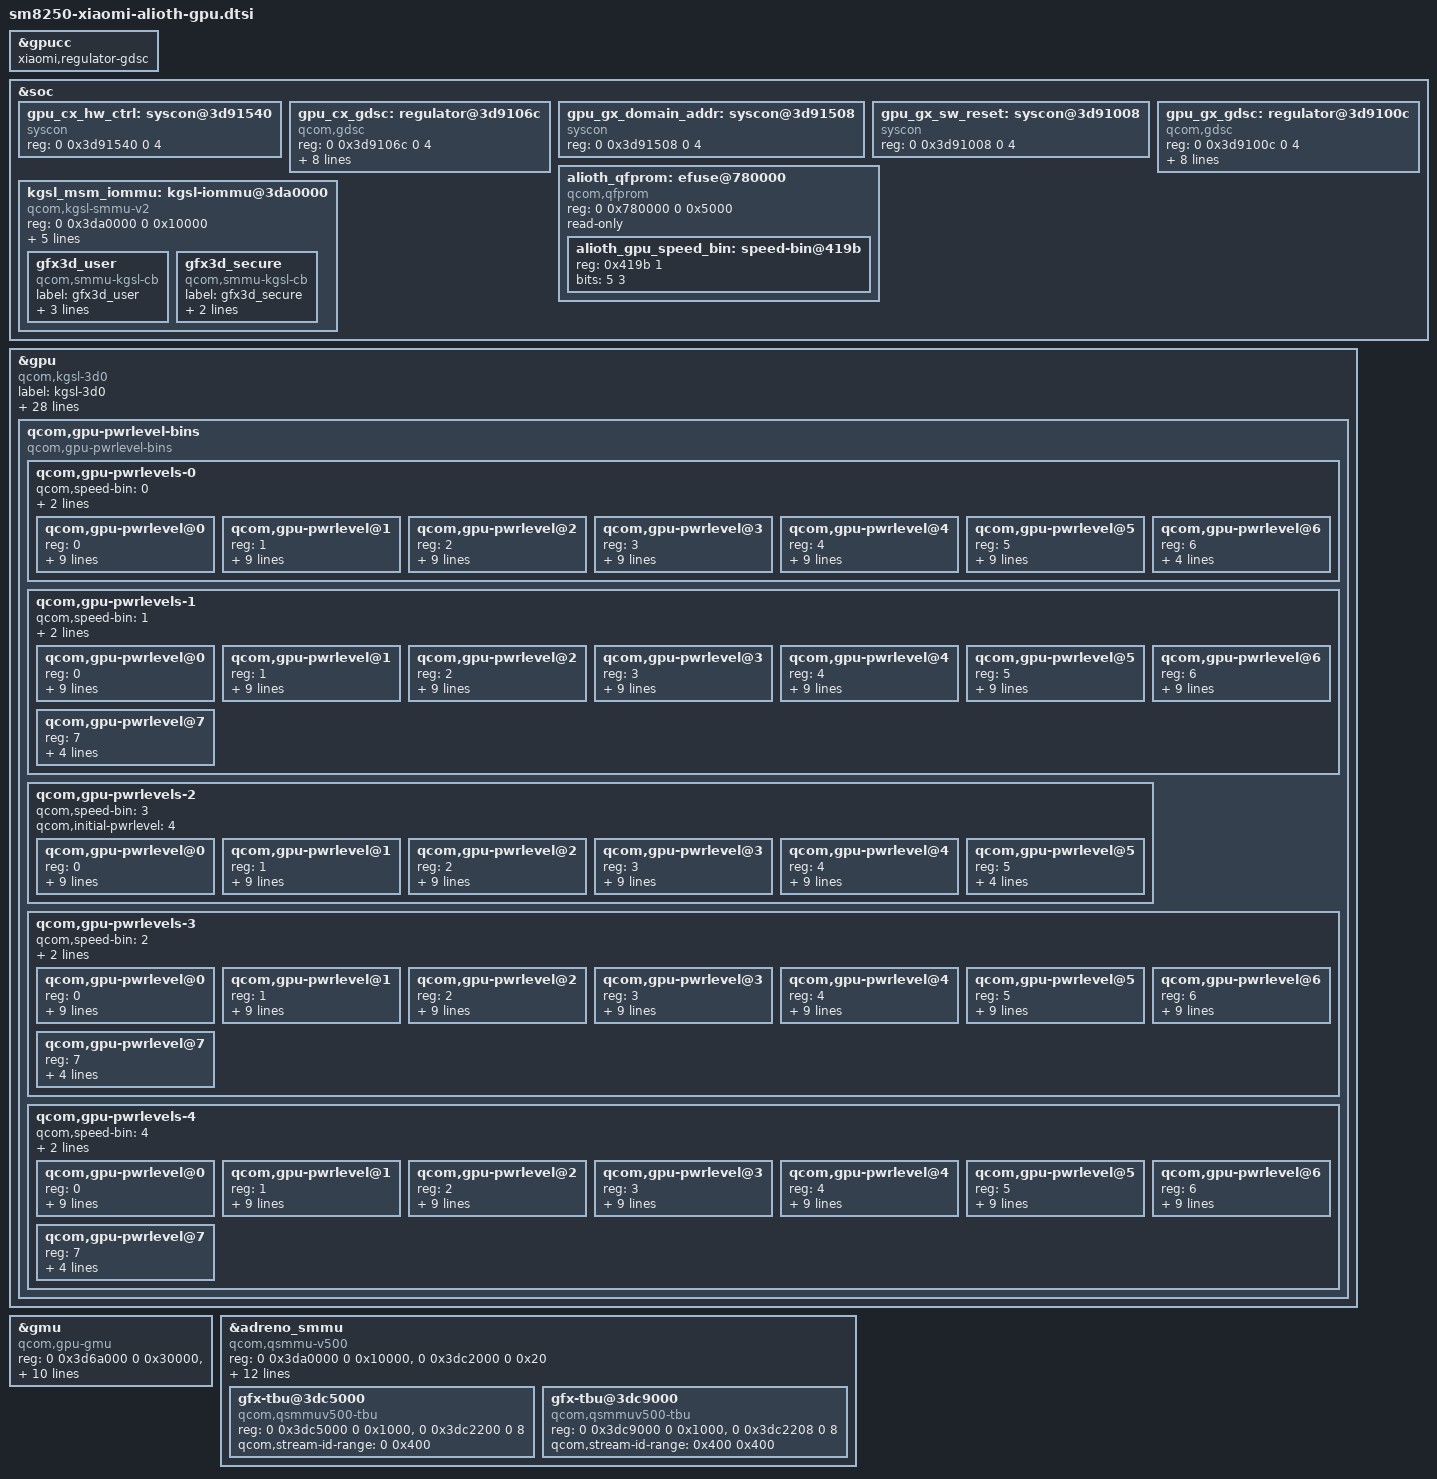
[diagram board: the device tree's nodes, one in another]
// SPDX-License-Identifier: GPL-2.0-only
/* Alioth KGSL/GMU translation from donor Kona v2/v2.1 GPU bindings.
 * Clock and interconnect references use the native 5.15 symbolic IDs.
 */
#include <dt-bindings/interconnect/qcom,sm8250.h>

&gpucc {
	/* Do not let genpd and regulator providers control the same registers. */
	xiaomi,regulator-gdsc;
	/delete-property/ #power-domain-cells;
};

&soc {
	gpu_cx_hw_ctrl: syscon@3d91540 {
		compatible = "syscon";
		reg = <0 0x3d91540 0 4>;
	};
	gpu_cx_gdsc: regulator@3d9106c {
		compatible = "qcom,gdsc";
		reg = <0 0x3d9106c 0 4>;
		regulator-name = "gpu_cx_gdsc";
		hw-ctrl-addr = <&gpu_cx_hw_ctrl>;
		parent-supply = <&VDD_CX_LEVEL>;
		vdd_parent-supply = <&VDD_CX_LEVEL>;
		qcom,no-status-check-on-disable;
		qcom,clk-dis-wait-val = <8>;
		qcom,gds-timeout = <500>;
		qcom,retain-regs;
	};
	gpu_gx_domain_addr: syscon@3d91508 {
		compatible = "syscon";
		reg = <0 0x3d91508 0 4>;
	};
	gpu_gx_sw_reset: syscon@3d91008 {
		compatible = "syscon";
		reg = <0 0x3d91008 0 4>;
	};
	gpu_gx_gdsc: regulator@3d9100c {
		compatible = "qcom,gdsc";
		reg = <0 0x3d9100c 0 4>;
		regulator-name = "gpu_gx_gdsc";
		domain-addr = <&gpu_gx_domain_addr>;
		sw-reset = <&gpu_gx_sw_reset>;
		parent-supply = <&VDD_GFX_LEVEL>;
		vdd_parent-supply = <&VDD_GFX_LEVEL>;
		qcom,skip-disable-before-sw-enable;
		qcom,reset-aon-logic;
		qcom,retain-regs;
	};
	alioth_qfprom: efuse@780000 {
		compatible = "qcom,qfprom";
		reg = <0 0x780000 0 0x5000>;
		#address-cells = <1>;
		#size-cells = <1>;
		read-only;
		alioth_gpu_speed_bin: speed-bin@419b {
			reg = <0x419b 1>;
			bits = <5 3>;
		};
	};
	kgsl_msm_iommu: kgsl-iommu@3da0000 {
		compatible = "qcom,kgsl-smmu-v2";
		reg = <0 0x3da0000 0 0x10000>;
		qcom,protect = <0xa0000 0xc000>;
		qcom,secure_align_mask = <0xfff>;
		qcom,retention;
		qcom,hyp_secure_alloc;
		vddcx-supply = <&gpu_cx_gdsc>;
		gfx3d_user {
			compatible = "qcom,smmu-kgsl-cb";
			label = "gfx3d_user";
			iommus = <&adreno_smmu 0 0x401>;
			qcom,iommu-dma = "disabled";
			qcom,gpu-offset = <0xa8000>;
		};
		gfx3d_secure {
			compatible = "qcom,smmu-kgsl-cb";
			label = "gfx3d_secure";
			iommus = <&adreno_smmu 2 0x400>;
			qcom,iommu-dma = "disabled";
		};
	};
};

&gpu {
	compatible = "qcom,kgsl-3d0", "qcom,kgsl-3d";
	label = "kgsl-3d0";
	status = "okay";
	reg = <0 0x3d00000 0 0x40000>, <0 0x3d61000 0 0x800>,
		<0 0x3de0000 0 0x10000>, <0 0x3d8b000 0 0x2000>,
		<0 0x06900000 0 0x80000>;
	reg-names = "kgsl_3d0_reg_memory", "cx_dbgc", "rscc",
		"isense_cntl", "qdss_gfx";
	interrupt-names = "kgsl_3d0_irq";
	qcom,id = <0>;
	qcom,chipid = <0x06050002>;
	qcom,idle-timeout = <80>;
	qcom,no-nap;
	qcom,highest-bank-bit = <16>;
	qcom,min-access-length = <32>;
	qcom,ubwc-mode = <4>;
	qcom,snapshot-size = <0x200000>;
	#cooling-cells = <2>;
	qcom,pm-qos-active-latency = <44>;
	/delete-property/ operating-points-v2;
	/delete-property/ iommus;
	/delete-property/ qcom,gmu;
	clocks = <&gpucc GPU_CC_CXO_CLK>, <&gcc GCC_DDRSS_GPU_AXI_CLK>,
		<&gcc GCC_GPU_MEMNOC_GFX_CLK>, <&gpucc GPU_CC_CX_GMU_CLK>,
		<&gpucc GPU_CC_AHB_CLK>;
	clock-names = "rbbmtimer_clk", "mem_clk", "mem_iface_clk",
		"gmu_clk", "gpu_cc_ahb";
	nvmem-cells = <&alioth_gpu_speed_bin>;
	nvmem-cell-names = "speed_bin";
	regulator-names = "vddcx", "vdd";
	vddcx-supply = <&gpu_cx_gdsc>;
	vdd-supply = <&gpu_gx_gdsc>;
	interconnects = <&gem_noc MASTER_GRAPHICS_3D &mc_virt SLAVE_EBI_CH0>;
	interconnect-names = "gpu_icc_path";
	qcom,bus-table-ddr7 = <0 781250 1171875 1761718 2136718 2660156 3000000 3972656 5285156 6074218 7046875 8171875>;
	qcom,bus-table-ddr8 = <0 781250 1171875 1761718 2136718 2660156 3000000 3972656 6074218 7046875 8171875 10687500>;
	qcom,gpu-pwrlevel-bins {
		compatible="qcom,gpu-pwrlevel-bins";
		#address-cells = <1>;
		#size-cells = <0>;

		qcom,gpu-pwrlevels-0 {
			#address-cells = <1>;
			#size-cells = <0>;
			qcom,speed-bin = <0>;
			qcom,initial-pwrlevel = <5>;
			qcom,throttle-pwrlevel = <0>;

			qcom,gpu-pwrlevel@0 {
				reg = <0>;
				qcom,gpu-freq = <587000000>;
				qcom,level = <RPMH_REGULATOR_LEVEL_NOM>;
				qcom,bus-freq-ddr7 = <11>;
				qcom,bus-min-ddr7 = <11>;
				qcom,bus-max-ddr7 = <11>;

				qcom,bus-freq-ddr8 = <11>;
				qcom,bus-min-ddr8 = <11>;
				qcom,bus-max-ddr8 = <11>;

				qcom,acd-level = <0x802b5ffd>;
			};

			qcom,gpu-pwrlevel@1 {
				reg = <1>;
				qcom,gpu-freq = <525000000>;
				qcom,level = <RPMH_REGULATOR_LEVEL_SVS_L2>;
				qcom,bus-freq-ddr7 = <9>;
				qcom,bus-min-ddr7 = <9>;
				qcom,bus-max-ddr7 = <11>;

				qcom,bus-freq-ddr8 = <8>;
				qcom,bus-min-ddr8 = <8>;
				qcom,bus-max-ddr8 = <11>;

				qcom,acd-level = <0x802b5ffd>;
			};

			qcom,gpu-pwrlevel@2 {
				reg = <2>;
				qcom,gpu-freq = <490000000>;
				qcom,level = <RPMH_REGULATOR_LEVEL_SVS_L1>;
				qcom,bus-freq-ddr7 = <9>;
				qcom,bus-min-ddr7 = <6>;
				qcom,bus-max-ddr7 = <9>;

				qcom,bus-freq-ddr8 = <8>;
				qcom,bus-min-ddr8 = <7>;
				qcom,bus-max-ddr8 = <9>;

				qcom,acd-level = <0xa02b5ffd>;
			};

			qcom,gpu-pwrlevel@3 {
				reg = <3>;
				qcom,gpu-freq = <441600000>;
				qcom,level = <RPMH_REGULATOR_LEVEL_SVS_L0>;
				qcom,bus-freq-ddr7 = <9>;
				qcom,bus-min-ddr7 = <6>;
				qcom,bus-max-ddr7 = <9>;

				qcom,bus-freq-ddr8 = <8>;
				qcom,bus-min-ddr8 = <7>;
				qcom,bus-max-ddr8 = <9>;

				qcom,acd-level = <0xa02b5ffd>;
			};

			qcom,gpu-pwrlevel@4 {
				reg = <4>;
				qcom,gpu-freq = <400000000>;
				qcom,level = <RPMH_REGULATOR_LEVEL_SVS>;
				qcom,bus-freq-ddr7 = <7>;
				qcom,bus-min-ddr7 = <6>;
				qcom,bus-max-ddr7 = <9>;

				qcom,bus-freq-ddr8 = <8>;
				qcom,bus-min-ddr8 = <6>;
				qcom,bus-max-ddr8 = <9>;

				qcom,acd-level = <0xa02b5ffd>;
			};

			qcom,gpu-pwrlevel@5 {
				reg = <5>;
				qcom,gpu-freq = <305000000>;
				qcom,level = <RPMH_REGULATOR_LEVEL_LOW_SVS>;
				qcom,bus-freq-ddr7 = <3>;
				qcom,bus-min-ddr7 = <2>;
				qcom,bus-max-ddr7 = <9>;

				qcom,bus-freq-ddr8 = <3>;
				qcom,bus-min-ddr8 = <2>;
				qcom,bus-max-ddr8 = <9>;

				qcom,acd-level = <0xa02b5ffd>;
			};

			qcom,gpu-pwrlevel@6 {
				reg = <6>;
				qcom,gpu-freq = <0>;
				qcom,bus-freq = <0>;
				qcom,bus-min = <0>;
				qcom,bus-max = <0>;
			};
		};

		qcom,gpu-pwrlevels-1 {
			#address-cells = <1>;
			#size-cells = <0>;
			qcom,speed-bin = <1>;
			qcom,initial-pwrlevel = <6>;
			qcom,throttle-pwrlevel = <1>;

			qcom,gpu-pwrlevel@0 {
				reg = <0>;
				qcom,gpu-freq = <670000000>;
				qcom,level = <RPMH_REGULATOR_LEVEL_NOM_L1>;
				qcom,bus-freq-ddr7 = <11>;
				qcom,bus-min-ddr7 = <11>;
				qcom,bus-max-ddr7 = <11>;

				qcom,bus-freq-ddr8 = <11>;
				qcom,bus-min-ddr8 = <11>;
				qcom,bus-max-ddr8 = <11>;

				qcom,acd-level = <0x802b5ffd>;
			};

			qcom,gpu-pwrlevel@1 {
				reg = <1>;
				qcom,gpu-freq = <587000000>;
				qcom,level = <RPMH_REGULATOR_LEVEL_NOM>;
				qcom,bus-freq-ddr7 = <11>;
				qcom,bus-min-ddr7 = <11>;
				qcom,bus-max-ddr7 = <11>;

				qcom,bus-freq-ddr8 = <11>;
				qcom,bus-min-ddr8 = <11>;
				qcom,bus-max-ddr8 = <11>;

				qcom,acd-level = <0x802b5ffd>;
			};

			qcom,gpu-pwrlevel@2 {
				reg = <2>;
				qcom,gpu-freq = <525000000>;
				qcom,level = <RPMH_REGULATOR_LEVEL_SVS_L2>;
				qcom,bus-freq-ddr7 = <9>;
				qcom,bus-min-ddr7 = <9>;
				qcom,bus-max-ddr7 = <11>;

				qcom,bus-freq-ddr8 = <8>;
				qcom,bus-min-ddr8 = <8>;
				qcom,bus-max-ddr8 = <11>;

				qcom,acd-level = <0x802b5ffd>;
			};

			qcom,gpu-pwrlevel@3 {
				reg = <3>;
				qcom,gpu-freq = <490000000>;
				qcom,level = <RPMH_REGULATOR_LEVEL_SVS_L1>;
				qcom,bus-freq-ddr7 = <9>;
				qcom,bus-min-ddr7 = <6>;
				qcom,bus-max-ddr7 = <9>;

				qcom,bus-freq-ddr8 = <8>;
				qcom,bus-min-ddr8 = <7>;
				qcom,bus-max-ddr8 = <9>;

				qcom,acd-level = <0xa02b5ffd>;
			};

			qcom,gpu-pwrlevel@4 {
				reg = <4>;
				qcom,gpu-freq = <441600000>;
				qcom,level = <RPMH_REGULATOR_LEVEL_SVS_L0>;
				qcom,bus-freq-ddr7 = <9>;
				qcom,bus-min-ddr7 = <6>;
				qcom,bus-max-ddr7 = <9>;

				qcom,bus-freq-ddr8 = <8>;
				qcom,bus-min-ddr8 = <7>;
				qcom,bus-max-ddr8 = <9>;

				qcom,acd-level = <0xa02b5ffd>;
			};

			qcom,gpu-pwrlevel@5 {
				reg = <5>;
				qcom,gpu-freq = <400000000>;
				qcom,level = <RPMH_REGULATOR_LEVEL_SVS>;
				qcom,bus-freq-ddr7 = <7>;
				qcom,bus-min-ddr7 = <6>;
				qcom,bus-max-ddr7 = <9>;

				qcom,bus-freq-ddr8 = <8>;
				qcom,bus-min-ddr8 = <6>;
				qcom,bus-max-ddr8 = <9>;

				qcom,acd-level = <0xa02b5ffd>;
			};

			qcom,gpu-pwrlevel@6 {
				reg = <6>;
				qcom,gpu-freq = <305000000>;
				qcom,level = <RPMH_REGULATOR_LEVEL_LOW_SVS>;
				qcom,bus-freq-ddr7 = <3>;
				qcom,bus-min-ddr7 = <2>;
				qcom,bus-max-ddr7 = <9>;

				qcom,bus-freq-ddr8 = <3>;
				qcom,bus-min-ddr8 = <2>;
				qcom,bus-max-ddr8 = <9>;

				qcom,acd-level = <0xa02b5ffd>;
			};

			qcom,gpu-pwrlevel@7 {
				reg = <7>;
				qcom,gpu-freq = <0>;
				qcom,bus-freq = <0>;
				qcom,bus-min = <0>;
				qcom,bus-max = <0>;
			};
		};

		qcom,gpu-pwrlevels-2 {
			#address-cells = <1>;
			#size-cells = <0>;
			qcom,speed-bin = <3>;
			qcom,initial-pwrlevel = <4>;

			qcom,gpu-pwrlevel@0 {
				reg = <0>;
				qcom,gpu-freq = <525000000>;
				qcom,level = <RPMH_REGULATOR_LEVEL_SVS_L2>;
				qcom,bus-freq-ddr7 = <11>;
				qcom,bus-min-ddr7 = <10>;
				qcom,bus-max-ddr7 = <11>;

				qcom,bus-freq-ddr8 = <11>;
				qcom,bus-min-ddr8 = <10>;
				qcom,bus-max-ddr8 = <11>;

				qcom,acd-level = <0x802b5ffd>;
			};

			qcom,gpu-pwrlevel@1 {
				reg = <1>;
				qcom,gpu-freq = <490000000>;
				qcom,level = <RPMH_REGULATOR_LEVEL_SVS_L1>;
				qcom,bus-freq-ddr7 = <9>;
				qcom,bus-min-ddr7 = <6>;
				qcom,bus-max-ddr7 = <9>;

				qcom,bus-freq-ddr8 = <8>;
				qcom,bus-min-ddr8 = <7>;
				qcom,bus-max-ddr8 = <9>;

				qcom,acd-level = <0xa02b5ffd>;
			};

			qcom,gpu-pwrlevel@2 {
				reg = <2>;
				qcom,gpu-freq = <441600000>;
				qcom,level = <RPMH_REGULATOR_LEVEL_SVS_L0>;
				qcom,bus-freq-ddr7 = <9>;
				qcom,bus-min-ddr7 = <6>;
				qcom,bus-max-ddr7 = <9>;

				qcom,bus-freq-ddr8 = <8>;
				qcom,bus-min-ddr8 = <7>;
				qcom,bus-max-ddr8 = <9>;

				qcom,acd-level = <0xa02b5ffd>;
			};

			qcom,gpu-pwrlevel@3 {
				reg = <3>;
				qcom,gpu-freq = <400000000>;
				qcom,level = <RPMH_REGULATOR_LEVEL_SVS>;
				qcom,bus-freq-ddr7 = <7>;
				qcom,bus-min-ddr7 = <6>;
				qcom,bus-max-ddr7 = <9>;

				qcom,bus-freq-ddr8 = <8>;
				qcom,bus-min-ddr8 = <6>;
				qcom,bus-max-ddr8 = <9>;

				qcom,acd-level = <0xa02b5ffd>;
			};

			qcom,gpu-pwrlevel@4 {
				reg = <4>;
				qcom,gpu-freq = <305000000>;
				qcom,level = <RPMH_REGULATOR_LEVEL_LOW_SVS>;
				qcom,bus-freq-ddr7 = <3>;
				qcom,bus-min-ddr7 = <2>;
				qcom,bus-max-ddr7 = <9>;

				qcom,bus-freq-ddr8 = <3>;
				qcom,bus-min-ddr8 = <2>;
				qcom,bus-max-ddr8 = <9>;

				qcom,acd-level = <0xa02b5ffd>;
			};

			qcom,gpu-pwrlevel@5 {
				reg = <5>;
				qcom,gpu-freq = <0>;
				qcom,bus-freq = <0>;
				qcom,bus-min = <0>;
				qcom,bus-max = <0>;
			};
		};

		qcom,gpu-pwrlevels-3 {
			#address-cells = <1>;
			#size-cells = <0>;
			qcom,speed-bin = <2>;
			qcom,initial-pwrlevel = <6>;
			qcom,throttle-pwrlevel = <1>;

			qcom,gpu-pwrlevel@0 {
				reg = <0>;
				qcom,gpu-freq = <670000000>;
				qcom,level = <RPMH_REGULATOR_LEVEL_NOM_L1>;
				qcom,bus-freq-ddr7 = <11>;
				qcom,bus-min-ddr7 = <11>;
				qcom,bus-max-ddr7 = <11>;

				qcom,bus-freq-ddr8 = <11>;
				qcom,bus-min-ddr8 = <11>;
				qcom,bus-max-ddr8 = <11>;

				qcom,acd-level = <0x802b5ffd>;
			};

			qcom,gpu-pwrlevel@1 {
				reg = <1>;
				qcom,gpu-freq = <587000000>;
				qcom,level = <RPMH_REGULATOR_LEVEL_NOM>;
				qcom,bus-freq-ddr7 = <11>;
				qcom,bus-min-ddr7 = <11>;
				qcom,bus-max-ddr7 = <11>;

				qcom,bus-freq-ddr8 = <11>;
				qcom,bus-min-ddr8 = <11>;
				qcom,bus-max-ddr8 = <11>;

				qcom,acd-level = <0x802b5ffd>;
			};

			qcom,gpu-pwrlevel@2 {
				reg = <2>;
				qcom,gpu-freq = <525000000>;
				qcom,level = <RPMH_REGULATOR_LEVEL_SVS_L2>;
				qcom,bus-freq-ddr7 = <9>;
				qcom,bus-min-ddr7 = <9>;
				qcom,bus-max-ddr7 = <11>;

				qcom,bus-freq-ddr8 = <8>;
				qcom,bus-min-ddr8 = <8>;
				qcom,bus-max-ddr8 = <11>;

				qcom,acd-level = <0x802b5ffd>;
			};

			qcom,gpu-pwrlevel@3 {
				reg = <3>;
				qcom,gpu-freq = <490000000>;
				qcom,level = <RPMH_REGULATOR_LEVEL_SVS_L1>;
				qcom,bus-freq-ddr7 = <9>;
				qcom,bus-min-ddr7 = <6>;
				qcom,bus-max-ddr7 = <9>;

				qcom,bus-freq-ddr8 = <8>;
				qcom,bus-min-ddr8 = <7>;
				qcom,bus-max-ddr8 = <9>;

				qcom,acd-level = <0xa02b5ffd>;
				};

			qcom,gpu-pwrlevel@4 {
				reg = <4>;
				qcom,gpu-freq = <441600000>;
				qcom,level = <RPMH_REGULATOR_LEVEL_SVS_L0>;
				qcom,bus-freq-ddr7 = <9>;
				qcom,bus-min-ddr7 = <6>;
				qcom,bus-max-ddr7 = <9>;

				qcom,bus-freq-ddr8 = <8>;
				qcom,bus-min-ddr8 = <7>;
				qcom,bus-max-ddr8 = <9>;

				qcom,acd-level = <0xa02b5ffd>;
			};

			qcom,gpu-pwrlevel@5 {
				reg = <5>;
				qcom,gpu-freq = <400000000>;
				qcom,level = <RPMH_REGULATOR_LEVEL_SVS>;
				qcom,bus-freq-ddr7 = <7>;
				qcom,bus-min-ddr7 = <6>;
				qcom,bus-max-ddr7 = <9>;

				qcom,bus-freq-ddr8 = <8>;
				qcom,bus-min-ddr8 = <6>;
				qcom,bus-max-ddr8 = <9>;

				qcom,acd-level = <0xa02b5ffd>;
			};

			qcom,gpu-pwrlevel@6 {
				reg = <6>;
				qcom,gpu-freq = <305000000>;
				qcom,level = <RPMH_REGULATOR_LEVEL_LOW_SVS>;
				qcom,bus-freq-ddr7 = <3>;
				qcom,bus-min-ddr7 = <2>;
				qcom,bus-max-ddr7 = <9>;

				qcom,bus-freq-ddr8 = <3>;
				qcom,bus-min-ddr8 = <2>;
				qcom,bus-max-ddr8 = <9>;

				qcom,acd-level = <0xa02b5ffd>;
			};

			qcom,gpu-pwrlevel@7 {
				reg = <7>;
				qcom,gpu-freq = <0>;
				qcom,bus-freq = <0>;
				qcom,bus-min = <0>;
				qcom,bus-max = <0>;
			};
		};

		qcom,gpu-pwrlevels-4 {
			#address-cells = <1>;
			#size-cells = <0>;
			qcom,speed-bin = <4>;
			qcom,initial-pwrlevel = <6>;
			qcom,throttle-pwrlevel = <1>;

			qcom,gpu-pwrlevel@0 {
				reg = <0>;
				qcom,gpu-freq = <670000000>;
				qcom,level = <RPMH_REGULATOR_LEVEL_NOM_L1>;
				qcom,bus-freq-ddr7 = <11>;
				qcom,bus-min-ddr7 = <11>;
				qcom,bus-max-ddr7 = <11>;

				qcom,bus-freq-ddr8 = <11>;
				qcom,bus-min-ddr8 = <11>;
				qcom,bus-max-ddr8 = <11>;

				qcom,acd-level = <0x802b5ffd>;
			};

			qcom,gpu-pwrlevel@1 {
				reg = <1>;
				qcom,gpu-freq = <587000000>;
				qcom,level = <RPMH_REGULATOR_LEVEL_NOM>;
				qcom,bus-freq-ddr7 = <11>;
				qcom,bus-min-ddr7 = <11>;
				qcom,bus-max-ddr7 = <11>;

				qcom,bus-freq-ddr8 = <11>;
				qcom,bus-min-ddr8 = <11>;
				qcom,bus-max-ddr8 = <11>;

				qcom,acd-level = <0x802b5ffd>;
			};

			qcom,gpu-pwrlevel@2 {
				reg = <2>;
				qcom,gpu-freq = <525000000>;
				qcom,level = <RPMH_REGULATOR_LEVEL_SVS_L2>;
				qcom,bus-freq-ddr7 = <9>;
				qcom,bus-min-ddr7 = <9>;
				qcom,bus-max-ddr7 = <11>;

				qcom,bus-freq-ddr8 = <8>;
				qcom,bus-min-ddr8 = <8>;
				qcom,bus-max-ddr8 = <11>;

				qcom,acd-level = <0x802b5ffd>;
			};

			qcom,gpu-pwrlevel@3 {
				reg = <3>;
				qcom,gpu-freq = <490000000>;
				qcom,level = <RPMH_REGULATOR_LEVEL_SVS_L1>;
				qcom,bus-freq-ddr7 = <9>;
				qcom,bus-min-ddr7 = <6>;
				qcom,bus-max-ddr7 = <9>;

				qcom,bus-freq-ddr8 = <8>;
				qcom,bus-min-ddr8 = <7>;
				qcom,bus-max-ddr8 = <9>;

				qcom,acd-level = <0xa02b5ffd>;
				};

			qcom,gpu-pwrlevel@4 {
				reg = <4>;
				qcom,gpu-freq = <441600000>;
				qcom,level = <RPMH_REGULATOR_LEVEL_SVS_L0>;
				qcom,bus-freq-ddr7 = <9>;
				qcom,bus-min-ddr7 = <6>;
				qcom,bus-max-ddr7 = <9>;

				qcom,bus-freq-ddr8 = <8>;
				qcom,bus-min-ddr8 = <7>;
				qcom,bus-max-ddr8 = <9>;

				qcom,acd-level = <0xa02b5ffd>;
			};

			qcom,gpu-pwrlevel@5 {
				reg = <5>;
				qcom,gpu-freq = <400000000>;
				qcom,level = <RPMH_REGULATOR_LEVEL_SVS>;
				qcom,bus-freq-ddr7 = <7>;
				qcom,bus-min-ddr7 = <6>;
				qcom,bus-max-ddr7 = <9>;

				qcom,bus-freq-ddr8 = <8>;
				qcom,bus-min-ddr8 = <6>;
				qcom,bus-max-ddr8 = <9>;

				qcom,acd-level = <0xa02b5ffd>;
			};

			qcom,gpu-pwrlevel@6 {
				reg = <6>;
				qcom,gpu-freq = <305000000>;
				qcom,level = <RPMH_REGULATOR_LEVEL_LOW_SVS>;
				qcom,bus-freq-ddr7 = <3>;
				qcom,bus-min-ddr7 = <2>;
				qcom,bus-max-ddr7 = <9>;

				qcom,bus-freq-ddr8 = <3>;
				qcom,bus-min-ddr8 = <2>;
				qcom,bus-max-ddr8 = <9>;

				qcom,acd-level = <0xa02b5ffd>;
			};

			qcom,gpu-pwrlevel@7 {
				reg = <7>;
				qcom,gpu-freq = <0>;
				qcom,bus-freq = <0>;
				qcom,bus-min = <0>;
				qcom,bus-max = <0>;
			};
		};
	};
};

&gmu {
	compatible = "qcom,gpu-gmu";
	status = "okay";
	reg = <0 0x3d6a000 0 0x30000>, <0 0xb290000 0 0x10000>,
		<0 0xb490000 0 0x10000>;
	reg-names = "kgsl_gmu_reg", "kgsl_gmu_pdc_cfg", "kgsl_gmu_pdc_seq";
	interrupt-names = "kgsl_hfi_irq", "kgsl_gmu_irq";
	clocks = <&gpucc GPU_CC_CX_GMU_CLK>, <&gpucc GPU_CC_CXO_CLK>,
		<&gcc GCC_DDRSS_GPU_AXI_CLK>, <&gcc GCC_GPU_MEMNOC_GFX_CLK>,
		<&gpucc GPU_CC_AHB_CLK>;
	clock-names = "gmu_clk", "cxo_clk", "axi_clk", "memnoc_clk", "gpu_cc_ahb";
	regulator-names = "vddcx", "vdd";
	vddcx-supply = <&gpu_cx_gdsc>;
	vdd-supply = <&gpu_gx_gdsc>;
	iommus = <&adreno_smmu 5 0x400>;
	/delete-property/ power-domains;
	/delete-property/ power-domain-names;
	/delete-property/ operating-points-v2;
};

&adreno_smmu {
	compatible = "qcom,qsmmu-v500";
	reg = <0 0x3da0000 0 0x10000>, <0 0x3dc2000 0 0x20>;
	reg-names = "base", "tcu-base";
	#address-cells = <2>;
	#size-cells = <2>;
	ranges;
	qcom,skip-init;
	qcom,use-3-lvl-tables;
	qcom,no-dynamic-asid;
	qcom,regulator-names = "vdd";
	vdd-supply = <&gpu_cx_gdsc>;
	/delete-property/ power-domains;
	clocks = <&gcc GCC_GPU_MEMNOC_GFX_CLK>,
		<&gcc GCC_GPU_SNOC_DVM_GFX_CLK>, <&gpucc GPU_CC_AHB_CLK>;
	clock-names = "gcc_gpu_memnoc_gfx", "gcc_gpu_snoc_dvm_gfx", "gpu_cc_ahb";
	interconnects = <&gem_noc MASTER_GPU_TCU &mc_virt SLAVE_EBI_CH0>;
	qcom,actlr = <2 0x400 0x32b>, <4 0x400 0x32b>, <5 0x400 0x32b>,
		<7 0x400 0x32b>, <0 0x401 0x32b>;
	gfx-tbu@3dc5000 {
		compatible = "qcom,qsmmuv500-tbu";
		reg = <0 0x3dc5000 0 0x1000>, <0 0x3dc2200 0 8>;
		reg-names = "base", "status-reg";
		qcom,stream-id-range = <0 0x400>;
	};
	gfx-tbu@3dc9000 {
		compatible = "qcom,qsmmuv500-tbu";
		reg = <0 0x3dc9000 0 0x1000>, <0 0x3dc2208 0 8>;
		reg-names = "base", "status-reg";
		qcom,stream-id-range = <0x400 0x400>;
	};
};
